# liliumSOC1_sysctrl register map
Vendor: Nordic Semiconductor; Series: liliumSOC1; File version: 1
Registers are 32-bit, read-write, reset 0x0 unless marked. A register's access mark holds for its fields unless they carry their own. Offsets are from the block's base; [hi:lo] are bit positions; lines under a group give offsets from that group; {n}, {i} and the like mark numbered series; 'fields as' and 'values as' point back to an identical list.

## ROMC_S — ROM Controller
Base 0x5F8C6000
0x500 POWER group — Unspecified
  0x00 CONTROL reset 0x1 — ROM power control register.
    [0] MEM0 — Keep the ROM block MEM[0] on or off when in System ON mode.
      0=Off (Power down); 1=On (Power up)

## MEMCONF120_S — Memory configuration 0
Base 0x5F8C7000
Same registers: MEMCONF130_S 0x5F905000
{0x500+0x10*i} POWER[{i}] (i=0..3) group — Unspecified
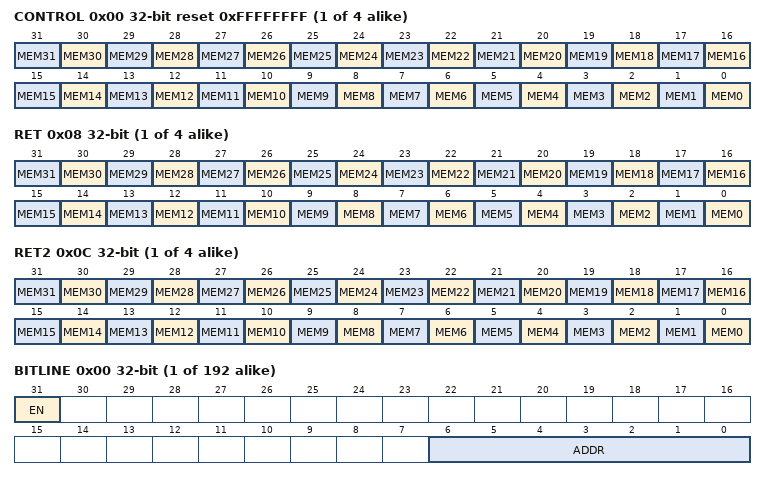
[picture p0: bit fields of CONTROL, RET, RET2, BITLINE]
  0x00 CONTROL reset 0xFFFFFFFF — Description cluster: RAM/ROM[n] power control register.
    [all] fields
      0=Off (Power down); 1=On (Power up)
    [n] MEM{n} (n=0..31) — Keep the RAM/ROM block MEM[{n}] on or off when in System ON mode.
  0x08 RET — Description cluster: RAM retention for RAM [n].
    [all] fields
      0=Off (Retention off); 1=On (Retention on)
    [n] MEM{n} (n=0..31) — Keep the RAM block MEM[{n}] retained when in System OFF mode.
  0x0C RET2 — Description cluster: RAM retention for the second bank in the RAM block
    [all] fields
      0=Off (Retention off); 1=On (Retention on)
    [n] MEM{n} (n=0..31) — Keep the second bank in RAM block MEM[{n}] retained when in System OFF mode.
{0x600+4i} REPAIR[{i}] (i=0..191) group — Unspecified
  0x00 BITLINE — Description cluster: Repair configuration for RAM blocks.
    [31] EN — Enable bitline repair
      0=Disabled (Repair disabled.); 1=Enabled (Repair enabled.)
    [6:0] ADDR — Repair address of the bitline
{0x900+4i} BLOCKTYPE[{i}] (i=0..63) group — Unspecified
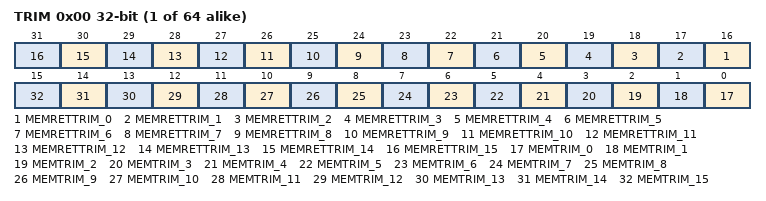
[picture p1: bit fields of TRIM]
  0x00 TRIM — Description cluster: Trim configuration for the RAM/ROM block types.
    [n+16] MEMRETTRIM_{n} (n=0..15) — Trimming for retention mode for decreased leakage. Must be kept active in RAM retention mode.
    [n] MEMTRIM_{n} (n=0..15) — Read/write margin trim.

## GLOBAL_MUTEX120_NS — MUTEX 0
Base 0x4F8D2000
Same registers: GLOBAL_MUTEX130_NS 0x4F927000
{0x400+4i} MUTEX[{i}] (i=0..31) — Description collection: Mutex register
  [0] MUTEX — Mutex register n
    0=Unlocked (Mutex n is in unlocked state); 1=Locked (Mutex n is in locked state)

## GLOBAL_I3C120_NS — I3C 0
Base 0x4F8D3000
Same registers: GLOBAL_I3C121_NS 0x4F8DE000, GLOBAL_I3C120_S 0x5F8D3000, GLOBAL_I3C121_S 0x5F8DE000
0x100 EVENTS_CORE — Event indicating that interrupt triggered at I3C core
  [0] EVENTS_CORE
    0=NotGenerated (Event not generated); 1=Generated (Event generated)
0x104 EVENTS_DMA — Event indicating that interrupt triggered at I3C DMA
  [0] EVENTS_DMA
    values as EVENTS_CORE.EVENTS_CORE
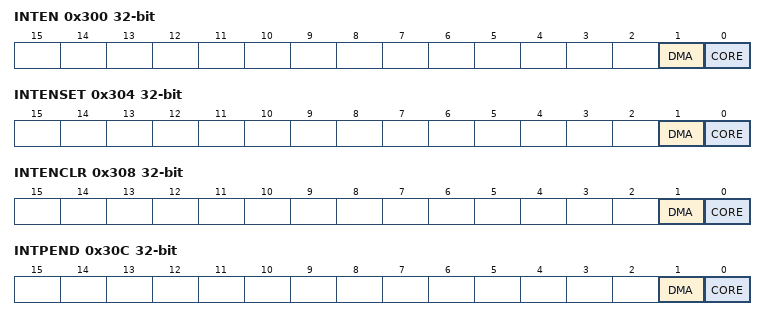
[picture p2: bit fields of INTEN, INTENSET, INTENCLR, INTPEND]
0x300 INTEN — Enable or disable interrupt
  [1] DMA — Enable or disable interrupt for event DMA
    0=Disabled; 1=Enabled
  [0] CORE — Enable or disable interrupt for event CORE
    0=Disabled; 1=Enabled
0x304 INTENSET — Enable interrupt
  [1] DMA — Write '1' to enable interrupt for event DMA
    on read: 0=Disabled (Read: Disabled); 1=Enabled (Read: Enabled) | on write: 1=Set (Enable)
  [0] CORE — Write '1' to enable interrupt for event CORE
    values as DMA
0x308 INTENCLR — Disable interrupt
  [1] DMA — Write '1' to disable interrupt for event DMA
    on read: 0=Disabled (Read: Disabled); 1=Enabled (Read: Enabled) | on write: 1=Clear (Disable)
  [0] CORE — Write '1' to disable interrupt for event CORE
    values as DMA
0x30C INTPEND ro — Pending interrupts
  [1] DMA — Read pending status of interrupt for event DMA
    on read: 0=NotPending (Read: Not pending); 1=Pending (Read: Pending)
  [0] CORE — Read pending status of interrupt for event CORE
    values as DMA
0x400 ENABLE — Enable I3C peripheral.
  [0] EN — Enable
    0=Disabled (I3C peripheral disabled.); 1=Enabled (I3C peripheral enabled.)
0x404 CDR group — Unspecified
  0x00 STARTOFFSET reset 0x4 — Start offset of recovered clock
    [15:0] VAL — Value
  0x04 MAXCYCLERATIO reset 0x28 — Maximum cycle ratio between SDA/SCL and CDR (clock and data recovery) clock
    [15:0] VAL — Value
  0x08 MAXSKEW reset 0x5 — Maximum skew between SCL and SCL in CDR clock cycles
    [7:0] VAL — Value
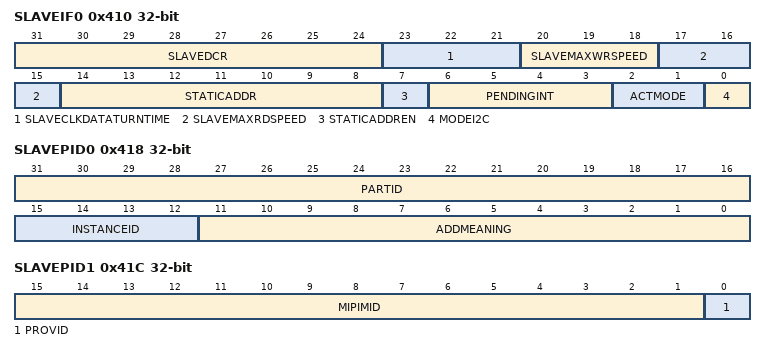
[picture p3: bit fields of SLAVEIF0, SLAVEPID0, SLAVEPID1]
0x410 SLAVEIF0 — I3C slave interface 0
  [31:24] SLAVEDCR — Device Characteristic Register value
  [23:21] SLAVECLKDATATURNTIME — Slave maximum clock data turnaround time
  [20:18] SLAVEMAXWRSPEED — Slave maximum write write rate
  [17:15] SLAVEMAXRDSPEED — Slave maximum read data rate
  [14:8] STATICADDR — Slave static address
  [7] STATICADDREN — Slave static address valid
    0=DISABLED (Unspecified); 1=ENABLED (Unspecified)
  [6:3] PENDINGINT — Pending interrupt information for GETSTATUS CCC
  [2:1] ACTMODE — Slave activity mode for GETSTATUS CCC
  [0] MODEI2C — I2C or I3C mode select signal
    0=DISABLED (Unspecified); 1=ENABLED (Unspecified)
0x414 SLAVEIF1 — I3C slave interface 1
  [0] WAKEUP ro — Slave wakeup signal
    0=DISABLED (Unspecified); 1=ENABLED (Unspecified)
0x418 SLAVEPID0 — Slave Device Provisioned ID 0
  [31:16] PARTID
  [15:12] INSTANCEID
  [11:0] ADDMEANING — Additional Meaning
0x41C SLAVEPID1 — Slave Device Provisioned ID 1
  [15:1] MIPIMID — MIPI Manufacturer ID
  [0] PROVID — Provisional ID Type Selector
0x420 KEEPSDA — Enable or disable the SDA high-keeper used for Master-to-Slave and Slave-to-Master bus hand-off.
  [0] ENABLE — Enable or disable the SDA high-keeper
    0=Disabled (High-keeper disabled.); 1=Enabled (High-keeper enabled.)
0x424 KEEPSCL — Enable or disable the SCL high-keeper used for Master-to-Slave and Slave-to-Master bus hand-off.
  [0] ENABLE — Enable or disable the SCL high-keeper
    values as KEEPSDA.ENABLE
